VERSION ""

NS_ :

BS_:
BU_: STEER PEDAL TER_CMDS FRONT_AXLE IMU LVBMS ECU CHARGER TireTemps REFRI DV RES STEER_ACTUATOR ASB BOOTLOADER
BO_ 1 COMMAND: 8 TER_CMDS
   SG_ CMD M : 0|8@1+ (1,0) [0|1] "" Vector__XXX
   SG_ ONOFF m64 : 8|8@1+ (1,0) [0|1] "" Vector__XXX
   SG_ VALUE m128 : 8|32@1+ (1,0) [0|1] "" Vector__XXX
   SG_ cfgLimiter m194 : 8|8@1+ (1,0) [0|1] "" Vector__XXX
   SG_ cfgMode m194 : 16|8@1+ (1,0) [0|1] "" Vector__XXX
   SG_ cfgTractionControl m194 : 24|8@1+ (1,0) [0|1] "" Vector__XXX
   SG_ kwLimit m193 : 8|8@1+ (1,0) [1|120] "kW" Vector__XXX
   SG_ speedLimit m193 : 24|8@1+ (1,0) [1|120] "km/h" Vector__XXX
   SG_ trqLimit m193 : 16|8@1+ (1,0) [1|180] "N/m" Vector__XXX

BO_ 2 RESPONSE: 8 TER_CMDS
   SG_ CMD M : 0|8@1+ (1,0) [0|1] "" Vector__XXX
   SG_ CODE : 56|8@1+ (1,0) [0|1] "" Vector__XXX

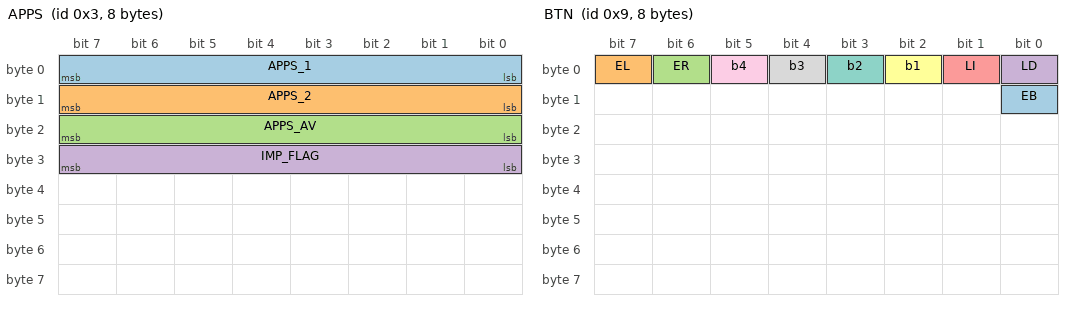
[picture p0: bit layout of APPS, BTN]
BO_ 3 APPS: 8 PEDAL
   SG_ APPS_1 : 0|8@1+ (1,0) [0|255] "" Vector__XXX
   SG_ APPS_2 : 8|8@1+ (1,0) [0|255] "" Vector__XXX
   SG_ APPS_AV : 16|8@1+ (1,0) [0|255] "" Vector__XXX
   SG_ IMP_FLAG : 24|8@1+ (1,0) [0|255] "" Vector__XXX

BO_ 4 BPPS: 8 PEDAL
   SG_ BPPS : 0|16@1+ (0.01,0) [0|1] "Bar" Vector__XXX

BO_ 5 STEER: 8 PEDAL
   SG_ ANGLE : 0|16@1- (0.01,0) [-3000|3000] "Grad" Vector__XXX
   SG_ IMP_FLAG : 16|8@1+ (1,0) [0|255] "" Vector__XXX

BO_ 9 BTN: 8 STEER
   SG_ EB : 8|1@1+ (1,0) [0|0] "" Vector__XXX
   SG_ EL : 7|1@1+ (1,0) [0|0] "" Vector__XXX
   SG_ ER : 6|1@1+ (1,0) [0|0] "" Vector__XXX
   SG_ LD : 0|1@1+ (1,0) [0|0] "" Vector__XXX
   SG_ LI : 1|1@1+ (1,0) [0|0] "" Vector__XXX
   SG_ b1 : 2|1@1+ (1,0) [0|0] "" Vector__XXX
   SG_ b2 : 3|1@1+ (1,0) [0|0] "" Vector__XXX
   SG_ b3 : 4|1@1+ (1,0) [0|0] "" Vector__XXX
   SG_ b4 : 5|1@1+ (1,0) [0|0] "" Vector__XXX

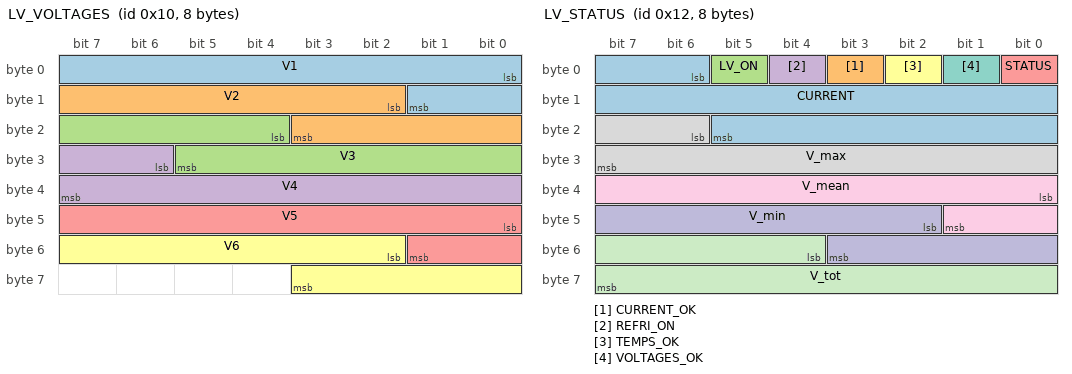
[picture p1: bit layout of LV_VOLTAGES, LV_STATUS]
BO_ 16 LV_VOLTAGES: 8 LVBMS
   SG_ V1 : 0|10@1+ (0.01,0) [0|1] "V" Vector__XXX
   SG_ V2 : 10|10@1+ (0.01,0) [0|1] "V" Vector__XXX
   SG_ V3 : 20|10@1+ (0.01,0) [0|1] "V" Vector__XXX
   SG_ V4 : 30|10@1+ (0.01,0) [0|1] "V" Vector__XXX
   SG_ V5 : 40|10@1+ (0.01,0) [0|1] "V" Vector__XXX
   SG_ V6 : 50|10@1+ (0.01,0) [0|1] "V" Vector__XXX

BO_ 17 LV_TEMPS: 6 LVBMS
   SG_ T1 : 0|16@1+ (0.1,0) [0|1] "Grad" Vector__XXX
   SG_ T2 : 16|16@1+ (0.1,0) [0|1] "Grad" Vector__XXX

BO_ 18 LV_STATUS: 8 LVBMS
   SG_ CURRENT : 6|16@1+ (0.1,0) [0|1] "A" Vector__XXX
   SG_ CURRENT_OK : 3|1@1+ (1,0) [0|0] "" Vector__XXX
   SG_ LV_ON : 5|1@1+ (1,0) [0|1] "" Vector__XXX
   SG_ REFRI_ON : 4|1@1+ (1,0) [0|1] "" Vector__XXX
   SG_ STATUS : 0|1@1+ (1,0) [0|0] "" Vector__XXX
   SG_ TEMPS_OK : 2|1@1+ (1,0) [0|1] "" Vector__XXX
   SG_ VOLTAGES_OK : 1|1@1+ (1,0) [0|0] "" Vector__XXX
   SG_ V_max : 22|10@1+ (0.01,0) [0|0] "" Vector__XXX
   SG_ V_mean : 32|10@1+ (0.01,0) [0|0] "" Vector__XXX
   SG_ V_min : 42|10@1+ (0.01,0) [0|0] "" Vector__XXX
   SG_ V_tot : 52|12@1+ (0.01,0) [0|0] "" Vector__XXX

BO_ 19 LV_INFO: 8 LVBMS
   SG_ SOC : 0|12@1+ (0.1,0) [0|1] "%" Vector__XXX
   SG_ battDuration : 12|12@1+ (1,0) [0|1] "min" Vector__XXX

BO_ 36 Front_TempsR: 8 FRONT_AXLE
   SG_ TempL : 16|16@1+ (0.1,0) [0|1] "grad" Vector__XXX
   SG_ TempR : 0|16@1+ (0.1,0) [0|1] "grad" Vector__XXX

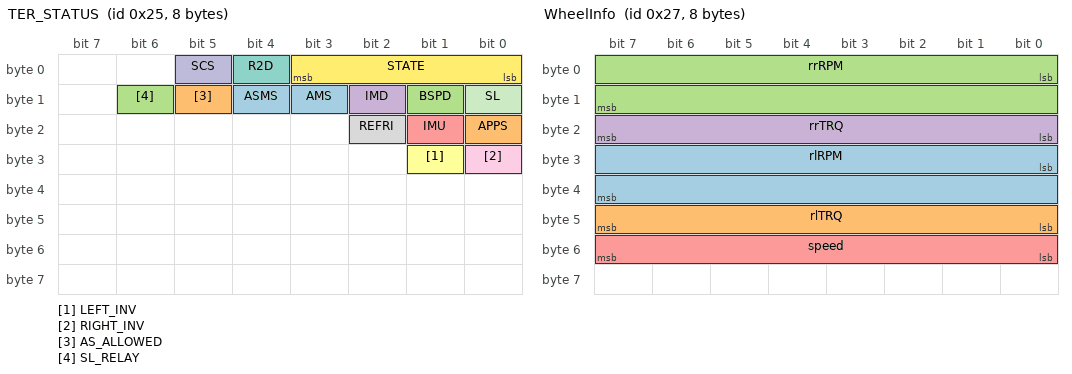
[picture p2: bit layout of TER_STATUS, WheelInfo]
BO_ 37 TER_STATUS: 8 ECU
   SG_ AMS : 11|1@1+ (1,0) [0|1] "" Vector__XXX
   SG_ APPS : 16|1@1+ (1,0) [0|1] "" Vector__XXX
   SG_ BSPD : 9|1@1+ (1,0) [0|0] "" Vector__XXX
   SG_ IMD : 10|1@1+ (1,0) [0|0] "" Vector__XXX
   SG_ IMU : 17|1@1+ (1,0) [0|1] "" Vector__XXX
   SG_ LEFT_INV : 25|1@1+ (1,0) [0|1] "" Vector__XXX
   SG_ R2D : 4|1@1+ (1,0) [0|1] "" Vector__XXX
   SG_ REFRI : 18|1@1+ (1,0) [0|1] "" Vector__XXX
   SG_ RIGHT_INV : 24|1@1+ (1,0) [0|1] "" Vector__XXX
   SG_ SCS : 5|1@1+ (1,0) [0|1] "" Vector__XXX
   SG_ SL : 8|1@1+ (1,0) [0|1] "" Vector__XXX
   SG_ STATE : 0|4@1+ (1,0) [0|1] "" Vector__XXX
   SG_ ASMS : 12|1@1+ (1,0) [0|1] "" Vector__XXX
   SG_ AS_ALLOWED : 13|1@1+ (1,0) [0|1] "" Vector__XXX
   SG_ SL_RELAY : 14|1@1+ (1,0) [0|1] "" Vector__XXX

BO_ 38 ECU_CONFIG: 8 ECU
   SG_ DRIVING_MODE m3 : 8|8@1+ (1,0) [0|1] "" Vector__XXX
   SG_ EEPROM m9 : 8|8@1+ (1,0) [0|1] "" Vector__XXX
   SG_ ENTRY M : 0|8@1+ (1,0) [0|1] "" Vector__XXX
   SG_ FLAP_ENABLE m14 : 8|8@1+ (1,0) [0|1] "0" Vector__XXX
   SG_ FLAP_L_OFFSET m10 : 8|16@1- (1,0) [0|1] "º" Vector__XXX
   SG_ FLAP_L_REVERSE m12 : 8|8@1+ (1,0) [0|1] "0" Vector__XXX
   SG_ FLAP_PEDAL_SETPOINT m15 : 8|8@1+ (1,0) [0|1] "0" Vector__XXX
   SG_ FLAP_R_OFFSET m11 : 8|16@1- (1,0) [0|1] "º" Vector__XXX
   SG_ FLAP_R_REVERSE m13 : 8|8@1+ (1,0) [0|1] "0" Vector__XXX
   SG_ LIMITER m2 : 8|8@1+ (1,0) [0|1] "" Vector__XXX
   SG_ R2D_BRAKE m1 : 8|8@1+ (1,0) [0|1] "Bar" Vector__XXX
   SG_ REGEN_ENABLE m16 : 8|8@1+ (1,0) [0|1] "" Vector__XXX
   SG_ REGEN_MAX_CELL_TEMP m19 : 8|8@1+ (1,0) [0|1] "" Vector__XXX
   SG_ REGEN_MAX_CELL_VOLT m18 : 8|16@1+ (1,0) [0|1] "mV" Vector__XXX
   SG_ REGEN_MAX_CURRENT m20 : 8|16@1- (1,0) [0|1] "" Vector__XXX
   SG_ REGEN_MAX_POSITIVE_TRQ_THR m25 : 8|8@1+ (1,0) [0|1] "" Vector__XXX
   SG_ REGEN_MAX_TRQ m17 : 8|8@1+ (1,0) [0|1] "" Vector__XXX
   SG_ REGEN_MODE m24 : 8|8@1+ (1,0) [0|1] "" Vector__XXX
   SG_ REGEN_THR_RPM m22 : 8|16@1+ (1,0) [0|1] "" Vector__XXX
   SG_ REGEN_THR_SPEED m21 : 8|8@1+ (1,0) [0|1] "" Vector__XXX
   SG_ REGEN_TRQ_SLOPE m23 : 8|8@1+ (1,0) [0|1] "" Vector__XXX
   SG_ SCS_ENABLE m0 : 8|1@1+ (1,0) [0|1] "" Vector__XXX
   SG_ TRACTION_CONTROL m4 : 8|8@1+ (1,0) [0|1] "" Vector__XXX
   SG_ TRQ_KD m7 : 8|32@5- (1,0) [0|1] "" Vector__XXX
   SG_ TRQ_KI m6 : 8|32@5- (1,0) [0|1] "" Vector__XXX
   SG_ TRQ_KP m5 : 8|32@5- (1,0) [0|1] "" Vector__XXX
   SG_ TRQ_LIMIT m8 : 8|8@1+ (1,0) [0|1] "NM" Vector__XXX
   SG_ DV_MISSION_REQ m26 : 8|8@1+ (1,0) [0|1] "" Vector__XXX

BO_ 39 WheelInfo: 8 ECU
   SG_ rlRPM : 24|16@1- (1,0) [0|1] "" Vector__XXX
   SG_ rlTRQ : 40|8@1+ (1,0) [0|1] "" Vector__XXX
   SG_ rrRPM : 0|16@1- (1,0) [0|1] "" Vector__XXX
   SG_ rrTRQ : 16|8@1+ (1,0) [0|1] "" Vector__XXX
   SG_ speed : 48|8@1+ (1,0) [0|1] "" Vector__XXX

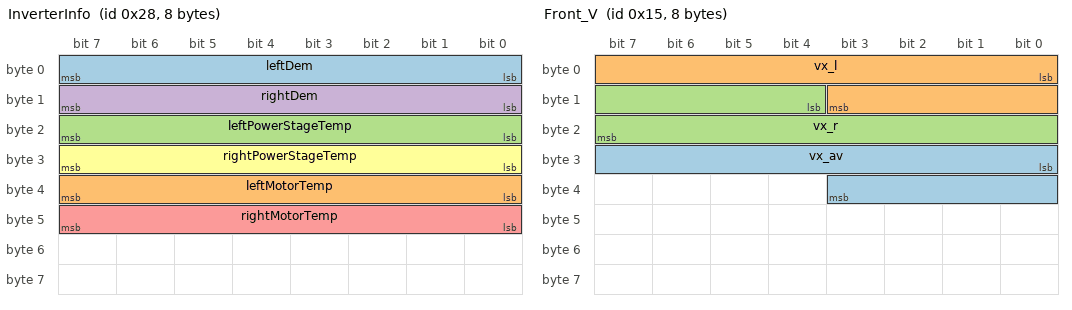
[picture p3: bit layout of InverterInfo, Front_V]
BO_ 40 InverterInfo: 8 ECU
   SG_ leftDem : 0|8@1+ (1,0) [0|1] "" Vector__XXX
   SG_ leftMotorTemp : 32|8@1+ (1,0) [0|1] "" Vector__XXX
   SG_ leftPowerStageTemp : 16|8@1+ (1,0) [0|1] "" Vector__XXX
   SG_ rightDem : 8|8@1+ (1,0) [0|1] "" Vector__XXX
   SG_ rightMotorTemp : 40|8@1+ (1,0) [0|1] "" Vector__XXX
   SG_ rightPowerStageTemp : 24|8@1+ (1,0) [0|1] "" Vector__XXX

BO_ 41 Front_TempsL: 8 FRONT_AXLE
   SG_ TempL : 16|16@1+ (0.1,0) [0|1] "grad" Vector__XXX
   SG_ TempR : 0|16@1+ (0.1,0) [0|1] "grad" Vector__XXX

BO_ 42 Rear_Susp: 8 FRONT_AXLE
   SG_ rlDisp : 0|16@1- (0.1,0) [0|1] "mm" Vector__XXX
   SG_ rrDisp : 16|16@1- (0.1,0) [0|1] "mm" Vector__XXX

BO_ 20 Front_RPM: 8 FRONT_AXLE
   SG_ RPM_L : 0|16@1+ (1,0) [0|1] "" Vector__XXX
   SG_ RPM_R : 16|16@1+ (1,0) [0|1] "" Vector__XXX

BO_ 21 Front_V: 8 FRONT_AXLE
   SG_ vx_av : 24|12@1+ (0.01,0) [0|1] "" Vector__XXX
   SG_ vx_l : 0|12@1+ (0.01,0) [0|1] "" Vector__XXX
   SG_ vx_r : 12|12@1+ (0.01,0) [0|1] "" Vector__XXX

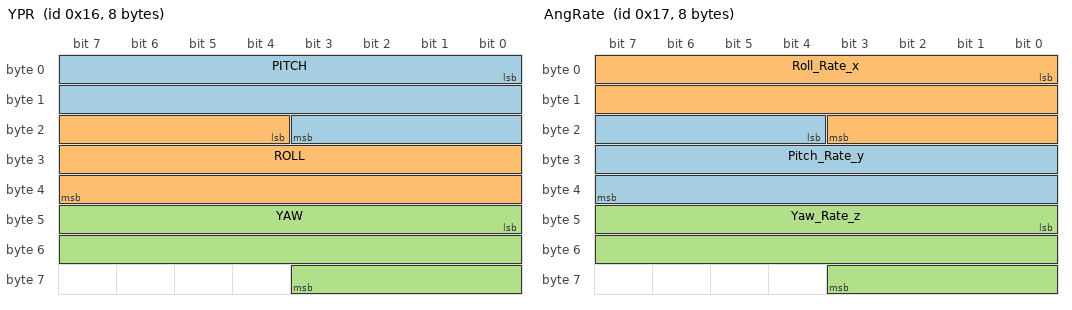
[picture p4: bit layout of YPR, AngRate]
BO_ 22 YPR: 8 IMU
   SG_ PITCH : 0|20@1- (0.01,0) [0|1] "" Vector__XXX
   SG_ ROLL : 20|20@1- (0.01,0) [0|1] "" Vector__XXX
   SG_ YAW : 40|20@1- (0.01,0) [0|1] "" Vector__XXX

BO_ 23 AngRate: 8 IMU
   SG_ Pitch_Rate_y : 20|20@1- (0.001,0) [0|1] "" Vector__XXX
   SG_ Roll_Rate_x : 0|20@1- (0.001,0) [0|1] "" Vector__XXX
   SG_ Yaw_Rate_z : 40|20@1- (0.001,0) [0|1] "" Vector__XXX

BO_ 24 GPS_Lat_Long: 8 IMU
   SG_ Latitude : 0|32@1- (1e-07,0) [0|1] "" Vector__XXX
   SG_ Longitude : 32|32@1- (1e-07,0) [0|1] "" Vector__XXX

BO_ 25 GPS_Altitude_Pres: 8 IMU
   SG_ Altidude : 0|32@1- (1e-07,0) [0|1] "" Vector__XXX
   SG_ Barometric_Pressure : 32|16@1- (1e-07,0) [0|1] "" Vector__XXX

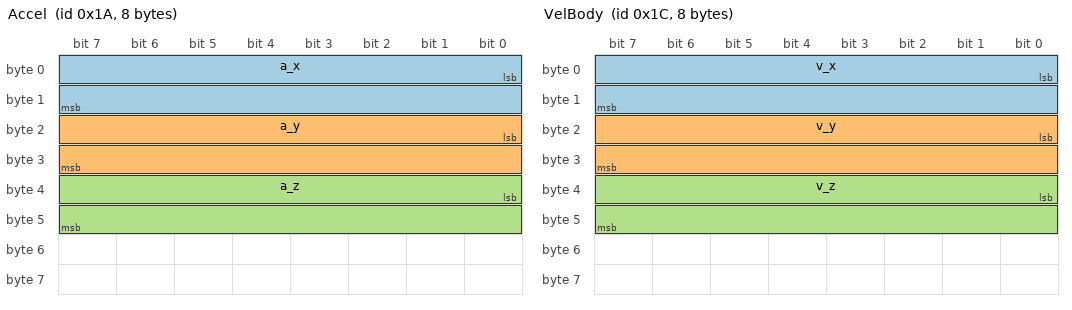
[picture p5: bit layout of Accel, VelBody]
BO_ 26 Accel: 8 IMU
   SG_ a_x : 0|16@1- (0.001,0) [0|1] "" Vector__XXX
   SG_ a_y : 16|16@1- (0.001,0) [0|1] "" Vector__XXX
   SG_ a_z : 32|16@1- (0.001,0) [0|1] "" Vector__XXX

BO_ 27 Mag: 8 IMU
   SG_ Heading : 0|16@1- (0.01,0) [0|1] "" Vector__XXX

BO_ 28 VelBody: 8 IMU
   SG_ v_x : 0|16@1- (0.001,0) [0|1] "" Vector__XXX
   SG_ v_y : 16|16@1- (0.001,0) [0|1] "" Vector__XXX
   SG_ v_z : 32|16@1- (0.001,0) [0|1] "" Vector__XXX

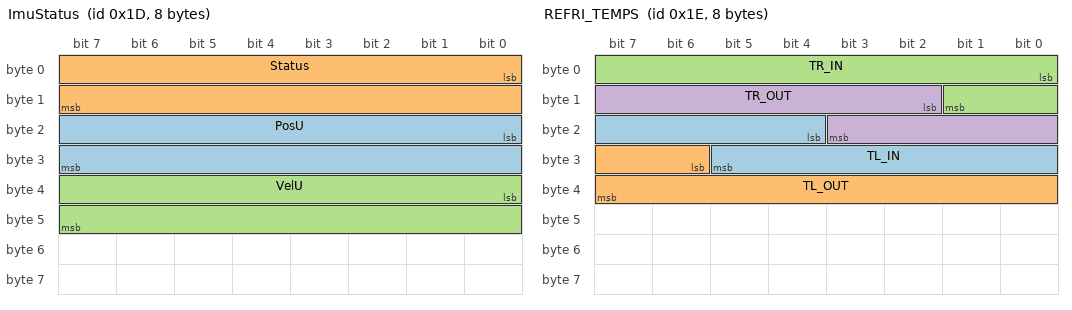
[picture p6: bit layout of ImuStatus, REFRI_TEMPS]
BO_ 29 ImuStatus: 8 IMU
   SG_ PosU : 16|16@1- (0.001,0) [0|1] "" Vector__XXX
   SG_ Status : 0|16@1- (1,0) [0|1] "" Vector__XXX
   SG_ VelU : 32|16@1- (0.001,0) [0|1] "" Vector__XXX

BO_ 30 REFRI_TEMPS: 8 REFRI
   SG_ TL_IN : 20|10@1+ (0.1,0) [0|1] "C" Vector__XXX
   SG_ TL_OUT : 30|10@1+ (0.1,0) [0|1] "C" Vector__XXX
   SG_ TR_IN : 0|10@1+ (0.1,0) [0|1] "C" Vector__XXX
   SG_ TR_OUT : 10|10@1+ (0.1,0) [0|1] "C" Vector__XXX

BO_ 31 REFRI_CONFIG: 8 REFRI
   SG_ ENTRY M : 0|8@1+ (1,0) [0|1] "" Vector__XXX
   SG_ INTENSITY m1 : 8|8@1+ (1,0) [0|100] "%" Vector__XXX
   SG_ INTENSITY_ACCU m5 : 8|8@1+ (1,0) [0|100] "%" Vector__XXX
   SG_ MODE m2 : 8|8@1+ (1,0) [0|1] "" Vector__XXX
   SG_ MODE_ACCU m6 : 8|8@1+ (1,0) [0|1] "" Vector__XXX
   SG_ POWER m0 : 8|8@1+ (1,0) [0|1] "" Vector__XXX
   SG_ POWER_ACCU m4 : 8|8@1+ (1,0) [0|1] "" Vector__XXX
   SG_ TARGET_TEMP m3 : 8|8@1+ (1,0) [0|1] "ºC" Vector__XXX
   SG_ TARGET_TEMP_ACCU m7 : 8|8@1+ (1,0) [0|1] "ºC" Vector__XXX

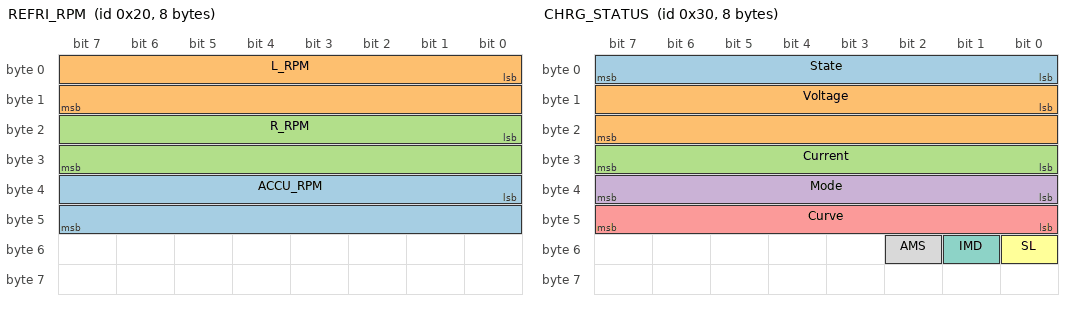
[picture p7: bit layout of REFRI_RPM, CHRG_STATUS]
BO_ 32 REFRI_RPM: 8 REFRI
   SG_ ACCU_RPM : 32|16@1+ (1,0) [0|1] "rpm" Vector__XXX
   SG_ L_RPM : 0|16@1+ (1,0) [0|1] "rpm" Vector__XXX
   SG_ R_RPM : 16|16@1+ (1,0) [0|1] "rpm" Vector__XXX

BO_ 33 REFRI_STATUS: 8 REFRI
   SG_ CURRENT : 0|16@1+ (0.1,0) [0|1] "" Vector__XXX
   SG_ MODE : 16|2@1+ (1,0) [0|1] "" Vector__XXX

BO_ 48 CHRG_STATUS: 8 CHARGER
   SG_ State : 0|8@1+ (1,0) [0|1] "" Vector__XXX
   SG_ Voltage : 8|16@1+ (1,0) [0|1] "V" Vector__XXX
   SG_ Current : 24|8@1+ (0.1,0) [0|1] "" Vector__XXX
   SG_ Mode : 32|8@1+ (1,0) [0|1] "" Vector__XXX
   SG_ Curve : 40|8@1+ (1,0) [0|1] "" Vector__XXX
   SG_ SL : 48|1@1+ (1,0) [0|1] "" Vector__XXX
   SG_ IMD : 49|1@1+ (1,0) [0|1] "" Vector__XXX
   SG_ AMS : 50|1@1+ (1,0) [0|1] "" Vector__XXX

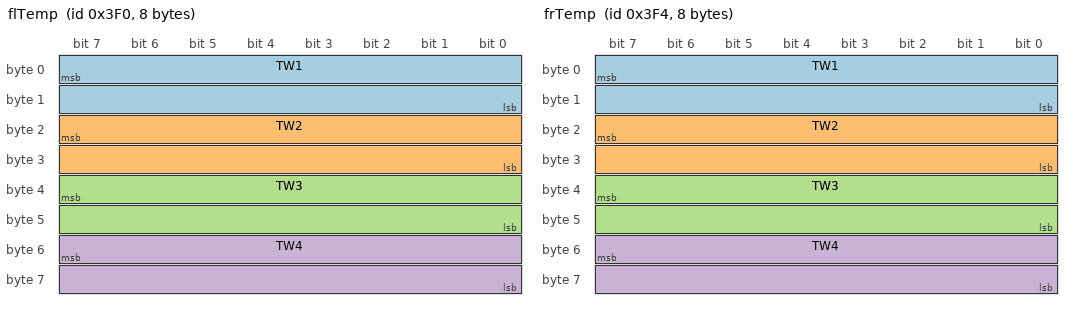
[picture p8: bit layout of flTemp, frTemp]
BO_ 1008 flTemp: 8 TireTemps
   SG_ TW1 : 7|16@0- (0.1,0) [-3276.8|3276.7] "" Vector__XXX
   SG_ TW2 : 23|16@0- (0.1,0) [-3276.8|3276.7] "" Vector__XXX
   SG_ TW3 : 39|16@0- (0.1,0) [-3276.8|3276.7] "" Vector__XXX
   SG_ TW4 : 55|16@0- (0.1,0) [-3276.8|3276.7] "" Vector__XXX

BO_ 1012 frTemp: 8 TireTemps
   SG_ TW1 : 7|16@0- (0.1,0) [-3276.8|3276.7] "" Vector__XXX
   SG_ TW2 : 23|16@0- (0.1,0) [-3276.8|3276.7] "" Vector__XXX
   SG_ TW3 : 39|16@0- (0.1,0) [-3276.8|3276.7] "" Vector__XXX
   SG_ TW4 : 55|16@0- (0.1,0) [-3276.8|3276.7] "" Vector__XXX

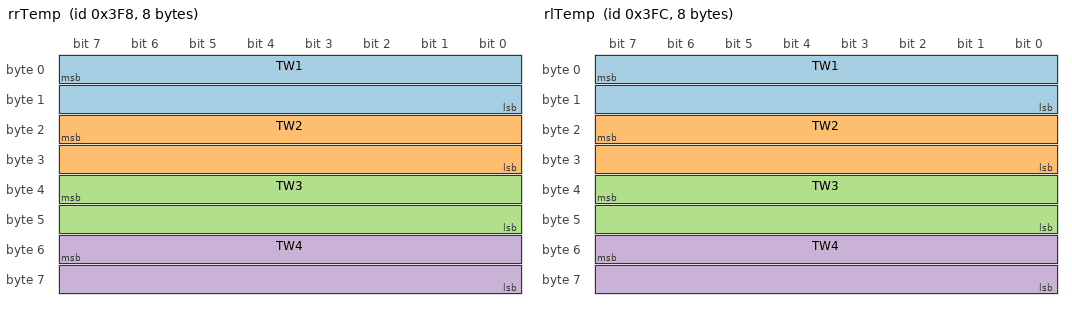
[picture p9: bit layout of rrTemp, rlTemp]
BO_ 1016 rrTemp: 8 TireTemps
   SG_ TW1 : 7|16@0- (0.1,0) [-3276.8|3276.7] "" Vector__XXX
   SG_ TW2 : 23|16@0- (0.1,0) [-3276.8|3276.7] "" Vector__XXX
   SG_ TW3 : 39|16@0- (0.1,0) [-3276.8|3276.7] "" Vector__XXX
   SG_ TW4 : 55|16@0- (0.1,0) [-3276.8|3276.7] "" Vector__XXX

BO_ 1020 rlTemp: 8 TireTemps
   SG_ TW1 : 7|16@0- (0.1,0) [-3276.8|3276.7] "" Vector__XXX
   SG_ TW2 : 23|16@0- (0.1,0) [-3276.8|3276.7] "" Vector__XXX
   SG_ TW3 : 39|16@0- (0.1,0) [-3276.8|3276.7] "" Vector__XXX
   SG_ TW4 : 55|16@0- (0.1,0) [-3276.8|3276.7] "" Vector__XXX

BO_ 43 TV_DEBUG: 8 ECU
   SG_ yaw_ref : 0|16@1- (0.01,0) [0|1] "deg" Vector__XXX
   SG_ delta_trq : 16|8@1- (1,0) [0|1] "Nm" Vector__XXX

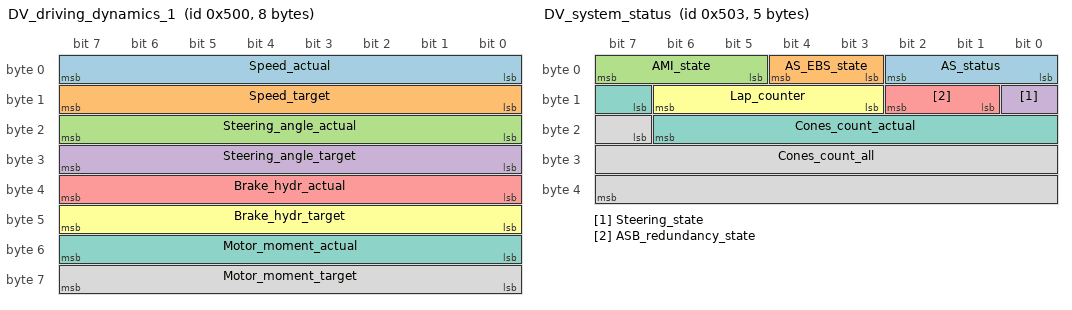
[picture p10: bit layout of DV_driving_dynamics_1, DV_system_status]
BO_ 1280 DV_driving_dynamics_1: 8 ECU
   SG_ Speed_actual : 0|8@1+ (1,0) [0|1] "km/h" Vector__XXX
   SG_ Speed_target : 8|8@1+ (1,0) [0|1] "km/h" Vector__XXX
   SG_ Steering_angle_actual : 16|8@1- (0.5,0) [0|1] "" Vector__XXX
   SG_ Steering_angle_target : 24|8@1- (0.5,0) [0|1] "º" Vector__XXX
   SG_ Brake_hydr_actual : 32|8@1+ (1,0) [0|1] "%" Vector__XXX
   SG_ Brake_hydr_target : 40|8@1+ (1,0) [0|1] "º" Vector__XXX
   SG_ Motor_moment_actual : 48|8@1+ (1,0) [0|1] "%" Vector__XXX
   SG_ Motor_moment_target : 56|8@1+ (1,0) [0|1] "" Vector__XXX

BO_ 1283 DV_system_status: 5 ECU
   SG_ AS_status : 0|3@1+ (1,0) [0|5] "" Vector__XXX
   SG_ AS_EBS_state : 3|2@1+ (1,0) [0|5] "" Vector__XXX
   SG_ AMI_state : 5|3@1+ (1,0) [0|6] "" Vector__XXX
   SG_ Steering_state : 8|1@1+ (1,0) [0|6] "" Vector__XXX
   SG_ ASB_redundancy_state : 9|2@1+ (1,0) [0|6] "" Vector__XXX
   SG_ Lap_counter : 11|4@1+ (1,0) [0|16] "" Vector__XXX
   SG_ Cones_count_actual : 15|8@1+ (1,0) [0|256] "" Vector__XXX
   SG_ Cones_count_all : 23|17@1+ (1,0) [0|130000] "" Vector__XXX

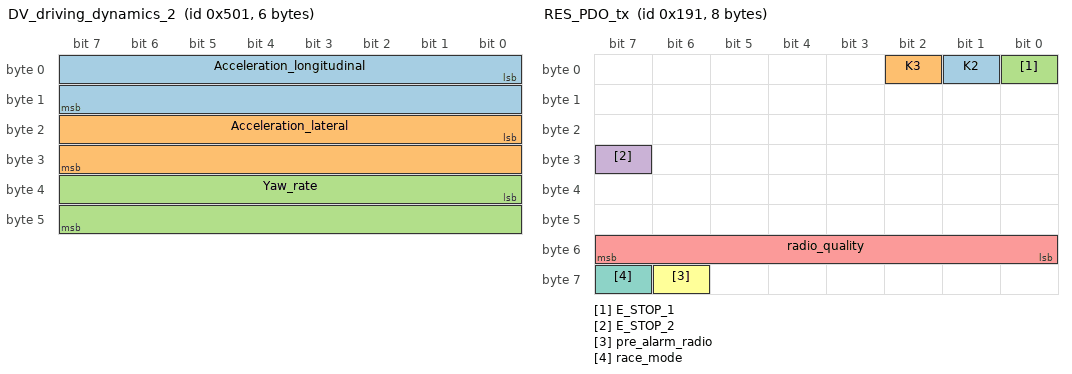
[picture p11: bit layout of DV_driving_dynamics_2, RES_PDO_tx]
BO_ 1281 DV_driving_dynamics_2: 6 ECU
   SG_ Acceleration_longitudinal : 0|16@1- (0.00195313,0) [0|1] "m/s2" Vector__XXX
   SG_ Acceleration_lateral : 16|16@1- (0.00195313,0) [0|1] "" Vector__XXX
   SG_ Yaw_rate : 32|16@1+ (0.0078125,0) [0|1] "º/s" Vector__XXX

BO_ 0 RES_NMT_node_control: 8 RES
   SG_ requested_state : 0|8@1+ (1,0) [0|1] "" Vector__XXX
   SG_ adressed_node_id : 8|8@1+ (1,0) [0|1] "" Vector__XXX

BO_ 145 RES_Sync: 8 RES

BO_ 401 RES_PDO_tx: 8 RES
   SG_ K2 : 1|1@1+ (1,0) [0|1] "" Vector__XXX
   SG_ K3 : 2|1@1+ (1,0) [0|1] "" Vector__XXX
   SG_ E_STOP_1 : 0|1@1+ (1,0) [0|1] "" Vector__XXX
   SG_ E_STOP_2 : 31|1@1+ (1,0) [0|1] "" Vector__XXX
   SG_ radio_quality : 48|8@1+ (1,0) [0|1] "" Vector__XXX
   SG_ pre_alarm_radio : 62|1@1+ (1,0) [0|1] "" Vector__XXX
   SG_ race_mode : 63|1@1+ (1,0) [0|1] "" Vector__XXX

BO_ 529 RES_PDO_rx: 8 RES

BO_ 1425 RES_SDO_tx: 8 RES

BO_ 1553 RES_SDO_rx: 8 RES

BO_ 1809 RES_NMT_node_monitoring: 1 RES
   SG_ data_byte : 0|8@1+ (1,0) [0|1] "" Vector__XXX

BO_ 2037 RES_LSS_tx: 8 RES

BO_ 2038 RES_LSS_rx: 8 RES

BO_ 2147483768 steer_actuator_set_duty: 8 STEER_ACTUATOR
   SG_ actuator_duty_cycle : 7|32@0+ (1e-05,0) [0|1] "" Vector__XXX

BO_ 2147484024 steer_actuator_set_current_loop: 8 STEER_ACTUATOR
   SG_ actuator_current_loop : 7|32@0- (0.001,0) [0|1] "" Vector__XXX

BO_ 2147484280 steer_actuator_set_current_brake: 8 STEER_ACTUATOR
   SG_ actuator_current_brake : 7|32@0- (0.001,0) [0|1] "" Vector__XXX

BO_ 2147484536 steer_actuator_set_speed: 8 STEER_ACTUATOR
   SG_ actuator_speed : 7|32@0- (1,0) [-100000|100000] "erpms" Vector__XXX

BO_ 2147484792 steer_actuator_set_position: 8 STEER_ACTUATOR
   SG_ actuator_position : 7|32@0- (0.0001,0) [-3.6e+08|3.6e+08] "" Vector__XXX

BO_ 2147485048 steer_actuator_set_origin: 8 STEER_ACTUATOR
   SG_ actuator_origin : 7|8@0+ (1,0) [0|1] "" Vector__XXX

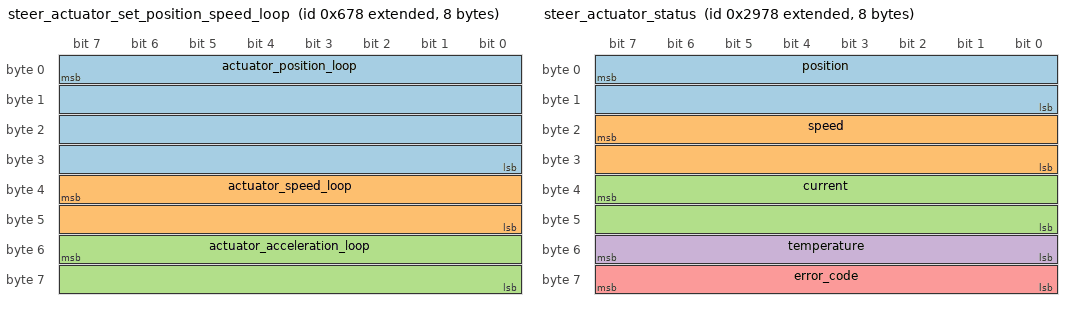
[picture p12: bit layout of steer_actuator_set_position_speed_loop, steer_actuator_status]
BO_ 2147485304 steer_actuator_set_position_speed_loop: 8 STEER_ACTUATOR
   SG_ actuator_position_loop : 7|32@0- (0.0001,0) [0|1] "" Vector__XXX
   SG_ actuator_speed_loop : 39|16@0+ (10,0) [0|1] "" Vector__XXX
   SG_ actuator_acceleration_loop : 55|16@0+ (10,0) [0|1] "" Vector__XXX

BO_ 2147494264 steer_actuator_status: 8 STEER_ACTUATOR
   SG_ position : 7|16@0- (0.1,0) [0|1] "" Vector__XXX
   SG_ speed : 23|16@0- (10,0) [0|1] "" Vector__XXX
   SG_ current : 39|16@0- (0.01,0) [0|1] "" Vector__XXX
   SG_ temperature : 55|8@0- (1,0) [0|1] "" Vector__XXX
   SG_ error_code : 63|8@0+ (1,0) [0|1] "" Vector__XXX

BO_ 35 Front_Susp: 8 FRONT_AXLE
   SG_ frDisp : 16|16@1- (0.1,0) [0|1] "mm" Vector__XXX
   SG_ flDisp : 0|16@1- (0.1,0) [0|1] "mm" Vector__XXX

BO_ 49 CHRG_REQ: 8 CHARGER
   SG_ mode_req : 0|8@1+ (1,0) [0|1] "" Vector__XXX

BO_ 6 DV_Dynamic_Req_1: 8 ECU
   SG_ trq_req : 0|32@5- (0.0001,0) [-1|1] "" Vector__XXX
   SG_ steer_angle_req : 32|32@1- (0.0001,0) [-3.6e+08|3.6e+08] "º" Vector__XXX

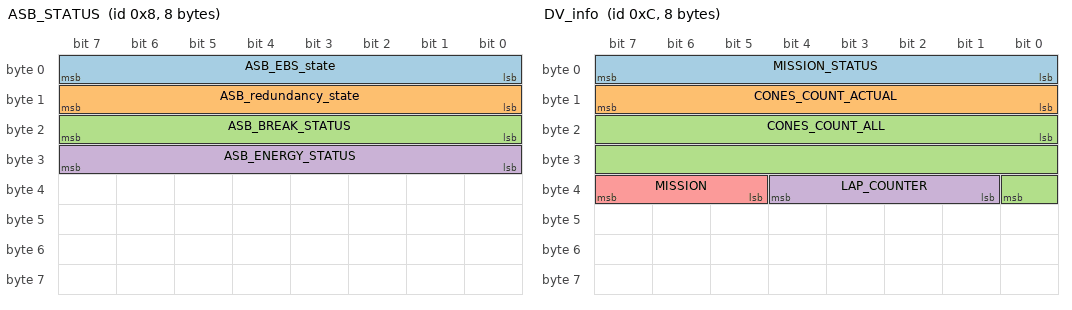
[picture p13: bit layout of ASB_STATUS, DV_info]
BO_ 8 ASB_STATUS: 8 ASB
   SG_ ASB_EBS_state : 0|8@1+ (1,0) [0|1] "" Vector__XXX
   SG_ ASB_redundancy_state : 8|8@1+ (1,0) [0|1] "" Vector__XXX
   SG_ ASB_BREAK_STATUS : 16|8@1+ (1,0) [0|1] "" Vector__XXX
   SG_ ASB_ENERGY_STATUS : 24|8@1+ (1,0) [0|1] "" Vector__XXX

BO_ 10 ASB_EBS_state_req: 8 ASB
   SG_ state_req : 0|8@1+ (1,0) [0|1] "" Vector__XXX

BO_ 11 ASB_redundancy_req: 8 ASB
   SG_ state_req : 0|8@1+ (1,0) [0|1] "" Vector__XXX

BO_ 12 DV_info: 8 DV
   SG_ MISSION_STATUS : 0|8@1+ (1,0) [0|3] "" Vector__XXX
   SG_ CONES_COUNT_ACTUAL : 8|8@1+ (1,0) [0|256] "" Vector__XXX
   SG_ CONES_COUNT_ALL : 16|17@1+ (1,0) [0|130000] "" Vector__XXX
   SG_ LAP_COUNTER : 33|4@1+ (1,0) [0|16] "" Vector__XXX
   SG_ MISSION : 37|3@1+ (1,0) [0|6] "" Vector__XXX

BO_ 13 DV_Dynamic_Req_2: 8 ECU
   SG_ ASB_BRAKE_REQ : 0|8@1+ (1,0) [0|1] "" Vector__XXX

BO_ 14 DV_CONFIG: 8 DV
   SG_ MISSION_REQ m0 : 8|8@1+ (1,0) [0|1] "" Vector__XXX
   SG_ ENTRY M : 0|8@1+ (1,0) [0|1] "" Vector__XXX

BO_ 15 ASB_brake_req: 8 ASB
   SG_ BRAKE : 0|8@1+ (1,0) [0|1] "" Vector__XXX

BO_ 771 BOOTLOADER_RESERVED_1: 8 BOOTLOADER

BO_ 772 BOOTLOADER_RESERVED_2: 8 BOOTLOADER

BO_ 773 BOOTLOADER_RESERVED_3: 8 BOOTLOADER

BO_ 774 BOOTLOADER_RESERVED_4: 8 BOOTLOADER

BO_ 775 BOOTLOADER_RESERVED_5: 8 BOOTLOADER

BO_ 776 BOOTLOADER_RESERVED_6: 8 BOOTLOADER

BO_ 2147483682 ASB_Brake_Pressure: 8 ASB
   SG_ LEFT_PRESSURE_SENSOR_BAR : 0|16@1+ (0.01,0) [0|1] "Bar" Vector__XXX
   SG_ RIGHT_PRESSURE_SENSOR_BAR : 16|16@1+ (0.01,0) [0|1] "Bar" Vector__XXX

CM_ BU_ STEER "The Steering Input MOdule";
CM_ BU_ PEDAL "The Drivers Sensor Board";
CM_ BU_ TER_CMDS "The Command Subsystem For TeR Vehicle";
CM_ BU_ FRONT_AXLE "The Board for Front axle sensors";
CM_ BU_ IMU "TeRs Inertial Measurement Unit";
CM_ BU_ LVBMS "The LV battery Management System";
CM_ BU_ ECU "The VCU for TeR Vehicle";
CM_ BU_ CHARGER "The Control Module for TeR Charger";
CM_ BU_ REFRI "The refrigeration module";
CM_ BU_ DV "status from dv controller";
CM_ BU_ RES "Remote Emergency System Message Definition";
CM_ BU_ ASB "Autonomous System Brake board";
CM_ BU_ BOOTLOADER "Bootloader reserved signals";
CM_ BO_ 1 "FUNCTION INDEX";
CM_ BO_ 2 "RESPONSE of a command";
CM_ SG_ 37 AS_ALLOWED "indicates_if_the_car_will_respond_nput_from_dv";
CM_ SG_ 38 EEPROM "write_here_the_config_id_to_request_value_from_eeprom,_otherwhise_use_value_table_for_options";
CM_ BO_ 6 "torque and steer request messages from dv";
CM_ SG_ 8 ASB_ENERGY_STATUS "is_AS_brake_energy_available";
CM_ BO_ 12 "dv computer status";
CM_ BO_ 13 "asb request messages from dv";
CM_ SG_ 14 MISSION_REQ "Request_mission_from_DV_computer";
BA_DEF_ BO_ "GenMsgBackgroundColor" STRING ;
BA_DEF_ BO_ "GenMsgForegroundColor" STRING ;
BA_DEF_DEF_ "GenMsgBackgroundColor" "#ffffff";
BA_DEF_DEF_ "GenMsgForegroundColor" "#000000";
VAL_ 1 CMD 14 "resetBMS" 1 "Calibrate_APPS_min" 2 "Calibrate_APPS_max" 5 "Calibrate_STEER_Leftest" 6 "Calibrate_STEER_Rightest" 8 "discharge" 9 "precharge" 10 "beep" 11 "ready2Drive" 0 "charge" 12 "startLog" 13 "endLog" 16 "precharge_dv" 15 "ready2Drive_dv";
VAL_ 1 ONOFF 0 "OFF" 1 "ON";
VAL_ 2 CODE 1 "OK" 2 "ERROR" 3 "INVALID_STATE" 4 "OUT_OF_RANGE";
VAL_ 18 CURRENT_OK 0 "FAULT" 1 "OK";
VAL_ 18 STATUS 0 "FAULT" 1 "OK";
VAL_ 18 TEMPS_OK 0 "FAULT" 1 "OK";
VAL_ 18 VOLTAGES_OK 0 "FAULT" 1 "OK";
VAL_ 37 STATE 0 "WAIT_SL" 1 "READY2PRECH" 2 "PRECHARGING" 3 "PRECHARGED" 4 "DRIVING";
VAL_ 37 AS_ALLOWED 0 "OFF" 1 "ON";
VAL_ 38 DRIVING_MODE 0 "LINEAL" 1 "TORQUE_VECTORING" 2 "DV_TORQUE_REQUEST";
VAL_ 38 EEPROM 252 "CLEAR_AND_DEFAULT_ALL" 255 "READ_ALL" 254 "SAVE_ALL";
VAL_ 38 ENTRY 0 "SCS_ENABLE" 1 "R2D_BRAKE_VAL" 2 "LIMITER" 3 "DRIVING_MODE" 4 "TRACTION_CONTROL" 5 "TRQV_KP" 6 "TRQV_KI" 7 "TRQV_KD" 8 "TRQ_LIMIT" 9 "EEPROM" 10 "FLAP_L_OFFSET" 11 "FLAP_R_OFFSET" 12 "FLAP_L_REVERSE" 13 "FLAP_R_REVERSE" 14 "FLAP_ENABLE" 15 "FLAP_PEDAL_SETPOINT" 16 "REGEN_ENABLE" 17 "REGEN_MAX_TRQ" 18 "REGEN_MAX_CELL_VOLT" 19 "REGEN_MAX_CELL_TEMP" 20 "REGEN_MAX_CURRENT" 21 "REGEN_THR_SPEED" 22 "REGEN_THR_RPM" 23 "REGEN_TRQ_SLOPE" 24 "REGEN_MODE" 25 "REGEN_MAX_POSITIVE_TRQ_THR" 26 "DV_MISSION_REQ";
VAL_ 38 FLAP_ENABLE 0 "OFF" 1 "ON";
VAL_ 38 FLAP_L_REVERSE 0 "NORMAL" 1 "REVERSE";
VAL_ 38 FLAP_R_REVERSE 0 "NORMAL" 1 "REVERSE";
VAL_ 38 LIMITER 0 "TORQUE" 1 "SPEED" 2 "POWER";
VAL_ 38 REGEN_ENABLE 1 "ENABLE" 0 "DISABLE";
VAL_ 38 REGEN_MODE 0 "APPS" 1 "FREE" 2 "BRAKE";
VAL_ 38 SCS_ENABLE 0 "DISABLE" 1 "ENABLE";
VAL_ 38 TRACTION_CONTROL 0 "OFF";
VAL_ 38 DV_MISSION_REQ 0 "MANUAL" 1 "ACCELERATION" 2 "SKIDPAD" 3 "TRACKDRIVE" 4 "BRAKETEST" 5 "INSPECTION" 6 "AUTOCROSS" 0 "MANUAL" 1 "ACCELERATION" 2 "SKIDPAD" 3 "TRACKDRIVE" 4 "BRAKETEST" 5 "INSPECTION" 6 "AUTOCROSS";
VAL_ 31 ENTRY 0 "POWER" 1 "INTENSITY" 2 "MODE" 3 "TARGET_TEMP" 4 "POWER_ACCU" 5 "INTENSITY_ACCU" 6 "MODE_ACCU" 7 "TARGET_TEMP_ACCU";
VAL_ 31 MODE 0 "AUTO" 1 "MANUAL";
VAL_ 31 MODE_ACCU 0 "AUTO" 1 "MANUAL";
VAL_ 31 POWER 0 "OFF" 1 "ON";
VAL_ 31 POWER_ACCU 0 "OFF" 1 "ON";
VAL_ 33 MODE 0 "AUTO" 1 "MANUAL";
VAL_ 48 State 0 "IDLE" 1 "READY" 2 "PRECHARGING" 3 "PRECHARGED" 4 "CHARGING";
VAL_ 48 Mode 0 "AUTO" 1 "MANUAL";
VAL_ 48 Curve 0 "CURVE_1" 1 "CURVE_2" 2 "CURVE_3" 3 "CURVE_4" 4 "CURVE_5" 5 "MANUAL";
VAL_ 1283 AS_status 1 "AS_status_off" 2 "AS_status_ready" 3 "AS_status_driving" 4 "AS_status_emergency" 5 "AS_status_finished";
VAL_ 1283 AS_EBS_state 1 "AS_EBS_state_deactivated" 2 "AS_EBS_state_initial_checkup_passed" 3 "AS_EBS_state_activated";
VAL_ 1283 AMI_state 1 "AMI_state_acceleration" 2 "AMI_state_skidpad" 3 "AMI_state_trackdrive" 4 "AMI_state_braketest" 5 "AMI_state_inspection" 6 "AMI_state_autocross" 0 "AMI_state_manual";
VAL_ 1283 Steering_state 0 "unavailable" 1 "available";
VAL_ 1283 ASB_redundancy_state 1 "ASB_redundancy_state_deactivated" 2 "ASB_redundancy_state_engaged" 3 "ASB_redundancy_state_initial_checkup_passed";
VAL_ 0 requested_state 1 "OPERATIONAL_MODE";
VAL_ 0 adressed_node_id 0 "ALL";
VAL_ 1809 data_byte 0 "ALIVE";
VAL_ 2147485048 actuator_origin 0 "temporal" 1 "permanent";
VAL_ 2147494264 error_code 0 "OK" 1 "OVERTEMP" 2 "OVERCURRENT" 3 "OVERVOLTAGE" 4 "UNDERVOLTAGE" 5 "ENCODER_FAULT" 6 "POWERSTAGE_OVERTEMP" 7 "MOTOR_STALL";
VAL_ 49 mode_req 0 "AUTO" 1 "MANUAL";
VAL_ 8 ASB_EBS_state 0 "DEACTIVATED" 1 "INITIAL_CHECK_PASSED" 2 "ACTIVATED";
VAL_ 8 ASB_redundancy_state 0 "DEACTIVATED" 1 "INITIAL_CHECK_PASSED" 2 "ACTIVATED";
VAL_ 8 ASB_BREAK_STATUS 0 "OFF" 1 "ON";
VAL_ 8 ASB_ENERGY_STATUS 0 "UNAVAILABLE" 1 "AVAILABLE";
VAL_ 10 state_req 0 "DISABLED" 1 "SELF_CHECK" 2 "ENABLED";
VAL_ 11 state_req 0 "DISABLED" 1 "SELF_CHECK" 2 "ENABLED";
VAL_ 12 MISSION_STATUS 0 "NONE" 1 "SELECTED" 2 "READY" 3 "RUNNING" 4 "FINISHED" 5 "FAILED";
VAL_ 12 MISSION 0 "MANUAL" 1 "ACCELERATION" 2 "SKIDPAD" 3 "TRACKDRIVE" 4 "BRAKETEST" 5 "INSPECTION" 6 "AUTOCROSS";
VAL_ 13 ASB_BRAKE_REQ 0 "DISABLED" 1 "ENABLED";
VAL_ 14 MISSION_REQ 0 "MANUAL" 1 "ACCELERATION" 2 "SKIDPAD" 3 "TRACKDRIVE" 4 "BRAKETEST" 5 "INSPECTION" 6 "AUTOCROSS" 7 "REMOTE_CONTROL";
VAL_ 14 ENTRY 0 "MISSION_REQ";
VAL_ 15 BRAKE 0 "DISABLED" 1 "ENABLED";
